# CY8C5287AXI_LP095 register map
File version: 0.1
CY8C52LP
Registers are 8-bit, read-write, no defined reset value unless marked. A register's access mark holds for its fields unless they carry their own. Offsets are from the block's base; lines under a group give offsets from that group; [hi:lo] are bit positions; {n}, {i} and the like mark numbered series; 'fields as' and 'values as' point back to an identical list; <NAME> marks a mode.

## Memory map
0x00000000 DigitalReset
0x00000000 DipSwReadReg
0x00000000 CBusAddrRegU
0x00000000 CBusAddrRegH
0x00000000 TickCounter
0x00000000 LEDControl
0x00000000 CBusAddrRegL
0x00000000 USBFS
0x00000000 UART_1 — UART

## DigitalReset
Base 0x00000000
0x40006575 DigitalReset_CONTROL_REG

## DipSwReadReg
Base 0x00000000
0x40006460 DipSwReadReg_STATUS_REG
0x40006480 DipSwReadReg_MASK_REG
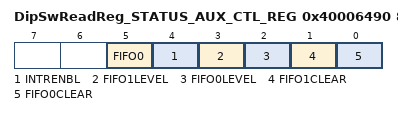
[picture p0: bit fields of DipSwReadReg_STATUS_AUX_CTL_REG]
0x40006490 DipSwReadReg_STATUS_AUX_CTL_REG
  [5] FIFO0 — FIFO0 clear
    1=ENABLED (Enable counter); 0=DISABLED (Disable counter)
  [4] INTRENBL — Enables or disables the Interrupt
    1=ENABLED (Interrupt enabled); 0=DISABLED (Interrupt disabled)
  [3] FIFO1LEVEL — FIFO level
    1=ENABLED (FIFO LVL: input mode: FIFO at least 1/2 empty; output mode: FIFO at least 1/2 full); 0=DISABLED (FIFO LVL: input mode: FIFO not full; output mode: FIFO not empty)
  [2] FIFO0LEVEL — FIFO level
    values as FIFO1LEVEL
  [1] FIFO1CLEAR — FIFO clear
    1=ENABLED (Clear FIFO state); 0=DISABLED (Normal FIFO operation)
  [0] FIFO0CLEAR — FIFO clear
    values as FIFO1CLEAR

## CBusAddrRegU
Base 0x00000000
0x40006476 CBusAddrRegU_CONTROL_REG

## CBusAddrRegH
Base 0x00000000
0x40006478 CBusAddrRegH_CONTROL_REG

## TickCounter
Base 0x00000000
0x40006404 TickCounter_COUNTER 32-bit — UDB.A0 - Current Counter Value
0x40006424 TickCounter_PERIOD 32-bit — UDB.D0 - Assigned Period
0x40006434 TickCounter_COMPARE 32-bit — UDB.D1 - Assigned Compare Value
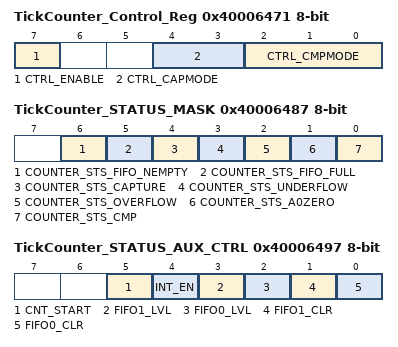
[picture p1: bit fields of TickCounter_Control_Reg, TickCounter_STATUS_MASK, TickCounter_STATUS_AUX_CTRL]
0x40006471 TickCounter_Control_Reg — UDB Control Register - Assigned Control Register Value
  [7] CTRL_ENABLE — Enable Counter
  [4:3] CTRL_CAPMODE — Capture mode
  [2:0] CTRL_CMPMODE — Compare mode
0x40006487 TickCounter_STATUS_MASK — UDB Status bits Interrupt Mask Enable Register
  [6] COUNTER_STS_FIFO_NEMPTY — FIFO Not Empty Status
  [5] COUNTER_STS_FIFO_FULL — FIFO Full Status
  [4] COUNTER_STS_CAPTURE — Capture Status
  [3] COUNTER_STS_UNDERFLOW — Underflow status
  [2] COUNTER_STS_OVERFLOW — Overflow status
  [1] COUNTER_STS_A0ZERO — A0 Zero ouput status
  [0] COUNTER_STS_CMP — Compare output status
0x40006497 TickCounter_STATUS_AUX_CTRL — UDB Auxilliary Control Register
  [5] CNT_START — FIFO0 clear
    0=E_CNT_START0 (Disable counter); 1=E_CNT_START1 (Enable counter)
  [4] INT_EN
    0=E_INT_EN0 (Interrupt disabled); 1=E_INT_EN1 (Interrupt enabled)
  [3] FIFO1_LVL — FIFO level
    0=E_FIFO_LVL_0 (FIFO LVL: input mode: FIFO not full; output mode: FIFO not empty); 1=E_FIFO_LVL_1 (FIFO LVL: input mode: FIFO at least 1/2 empty; output mode: FIFO at least 1/2 full)
  [2] FIFO0_LVL — FIFO level
    values as FIFO1_LVL
  [1] FIFO1_CLR — FIFO1 clear
    0=E_FIFO_CLR_0 (Normal FIFO operation); 1=E_FIFO_CLR_1 (Clear FIFO state)
  [0] FIFO0_CLR — FIFO0 clear
    values as FIFO1_CLR

## LEDControl
Base 0x00000000
0x40006578 LEDControl_CONTROL_REG

## CBusAddrRegL
Base 0x00000000
0x40006470 CBusAddrRegL_CONTROL_REG

## UART_1 — UART
Base 0x00000000
0x40006429 RX_UART_1_RX_ADDRESS1 — RX Address1 Register
0x40006439 RX_UART_1_RX_ADDRESS2 — RX Address2 Register
0x40006448 TX_UART_1_TX_DATA — TX Data Register
0x40006449 RX_UART_1_RX_DATA — RX Data Register
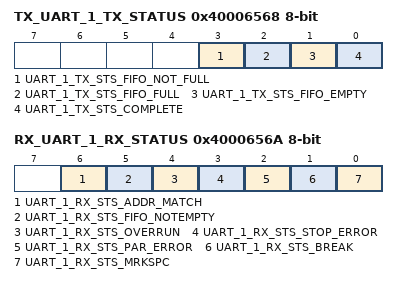
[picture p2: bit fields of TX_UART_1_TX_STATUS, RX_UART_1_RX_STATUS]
0x40006568 TX_UART_1_TX_STATUS — TX status register
  [3] UART_1_TX_STS_FIFO_NOT_FULL ro, [2] UART_1_TX_STS_FIFO_FULL ro, [1] UART_1_TX_STS_FIFO_EMPTY ro, [0] UART_1_TX_STS_COMPLETE ro
0x4000656A RX_UART_1_RX_STATUS — RX status register
  [6] UART_1_RX_STS_ADDR_MATCH ro, [5] UART_1_RX_STS_FIFO_NOTEMPTY ro, [4] UART_1_RX_STS_OVERRUN ro, [3] UART_1_RX_STS_STOP_ERROR ro, [2] UART_1_RX_STS_PAR_ERROR ro, [1] UART_1_RX_STS_BREAK ro, [0] UART_1_RX_STS_MRKSPC ro
